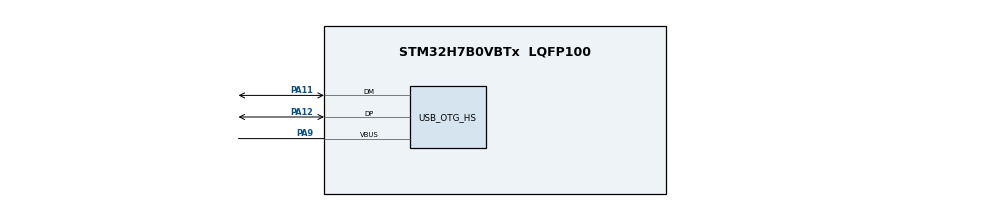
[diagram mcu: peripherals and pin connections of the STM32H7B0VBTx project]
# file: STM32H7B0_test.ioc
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Mcu.Family=STM32H7
Mcu.Name=STM32H7B0VBTx
Mcu.Package=LQFP100
NVIC.OTG_HS_IRQn=true\:0\:0\:false\:false\:true\:true\:true
NVIC.PriorityGroup=NVIC_PRIORITYGROUP_4
PA11.Mode=Device_Only_FS
PA11.Signal=USB_OTG_HS_DM
PA12.Mode=Device_Only_FS
PA12.Signal=USB_OTG_HS_DP
PA13.Mode=Serial_Wire
PA13.Signal=DEBUG_JTMS-SWDIO
PA14.Mode=Serial_Wire
PA14.Signal=DEBUG_JTCK-SWCLK
PA9.Mode=Activate_VBUS_FS
PA9.Signal=USB_OTG_HS_VBUS
ProjectManager.HeapSize=0x200
ProjectManager.StackSize=0x400
ProjectManager.TargetToolchain=STM32CubeIDE
RCC.ADCFreq_Value=129000000
RCC.APB1Freq_Value=32000000
RCC.APB2Freq_Value=32000000
RCC.APB3Freq_Value=32000000
RCC.APB4Freq_Value=32000000
RCC.CDPPRE=RCC_APB3_DIV2
RCC.CDPPRE1=RCC_APB1_DIV2
RCC.CDPPRE2=RCC_APB2_DIV2
RCC.CortexFreq_Value=64000000
RCC.DIVM1=4
RCC.DIVM3=1
RCC.DIVN1=8
RCC.DIVN3=24
RCC.DIVQ1=3
RCC.DIVQ3=8
RCC.HCLKFreq_Value=64000000
RCC.HSE_VALUE=16000000
RCC.PLL2FRACN=0
RCC.PLL3FRACN=0
RCC.PLLFRACN=0
RCC.SRDPPRE=RCC_APB4_DIV2
RCC.SYSCLKFreq_VALUE=64000000
RCC.SYSCLKSource=RCC_SYSCLKSOURCE_PLLCLK
RCC.USBCLockSelection=RCC_USBCLKSOURCE_HSI48
RCC.USBFreq_Value=48000000
USB_DEVICE.CLASS_NAME_HS=HID
USB_DEVICE.VirtualMode-HID_HS=Hid
USB_DEVICE.VirtualModeHS=Hid_HS
USB_OTG_HS.VirtualMode-Device_Only_FS=Device_Only_FS
USB_OTG_HS.dma_enable-Device_Only_FS=ENABLE
VP_USB_DEVICE_VS_USB_DEVICE_HID_HS.Mode=HID_HS
board=custom

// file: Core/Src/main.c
/* USER CODE BEGIN Header */
/**
  ******************************************************************************
  * @file           : main.c
  * @brief          : Main program body
  ******************************************************************************
  * @attention
  *
  * <h2><center>&copy; Copyright (c) 2024 STMicroelectronics.
  * All rights reserved.</center></h2>
  *
  * This software component is licensed by ST under BSD 3-Clause license,
  * the "License"; You may not use this file except in compliance with the
  * License. You may obtain a copy of the License at:
  *                        opensource.org/licenses/BSD-3-Clause
  *
  ******************************************************************************
  */
/* USER CODE END Header */
#include "main.h"
#include "usb_device.h"

/* USER CODE BEGIN PTD */
typedef struct
{
	char mouse_abs_left : 1;	//鼠标左键单击
	char mouse_abs_right : 1;	//鼠标右键单击
	char mouse_abs_wheel : 1;	//鼠标中键单击
	char reserve : 5;			//常量0
	char mouse_rel_x;			//鼠标X轴移动偏移量
	char mouse_rel_y;			//鼠标Y轴移动偏移量
	char mouse_rel_wheel;		//鼠标滚轮移动偏移�?
}	Mouse_data_t;

/* USER CODE END PTD */

/* USER CODE BEGIN PV */
extern USBD_HandleTypeDef hUsbDeviceHS;
Mouse_data_t mouse_data = {0};
int8_t xinc = 0, yinc = 0, step = 100;
uint16_t pacer = 0, cnt = 0;
const uint16_t interval_ms = 5000;
/* USER CODE END PV */

void SystemClock_Config(void);
static void MX_GPIO_Init(void);

int main(void)
{

  /* MCU Configuration--------------------------------------------------------*/

  /* Reset of all peripherals, Initializes the Flash interface and the Systick. */
  HAL_Init();

  /* Configure the system clock */
  SystemClock_Config();

  /* Initialize all configured peripherals */
  MX_GPIO_Init();
  MX_USB_DEVICE_Init();
  /* USER CODE BEGIN 2 */
  memset(&mouse_data, 0, sizeof(Mouse_data_t));
  /* USER CODE END 2 */

  /* Infinite loop */
  while (1)
  {

    /* USER CODE BEGIN 3 */
		HAL_Delay(100);
		if(pacer % (interval_ms / 100) == 0)
		{

		  switch(cnt % 4)
		  {
			  case 0: // move x
				  xinc = step;
				  yinc = 0;
				  break;
			  case 1:
				  xinc = 0;
				  yinc = step;
				  break;
			  case 2:
				  xinc = -step;
				  yinc = 0;
				  break;
			  case 3:
				  xinc = 0;
				  yinc = -step;
				  break;
		  }
		  ++cnt;
		  mouse_data.mouse_rel_x = xinc;
		  mouse_data.mouse_rel_y = yinc;
		  USBD_HID_SendReport(&hUsbDeviceHS, (uint8_t *)&mouse_data, sizeof(Mouse_data_t));
		  HAL_Delay(100);
		}
//	  HAL_IWDG_Refresh(&hiwdg); // feed the dog
	  ++pacer;
  }
  /* USER CODE END 3 */
}

void SystemClock_Config(void)
{
  RCC_OscInitTypeDef RCC_OscInitStruct = {0};
  RCC_ClkInitTypeDef RCC_ClkInitStruct = {0};

  /** Supply configuration update enable
  */
  HAL_PWREx_ConfigSupply(PWR_LDO_SUPPLY);
  /** Configure the main internal regulator output voltage
  */
  __HAL_PWR_VOLTAGESCALING_CONFIG(PWR_REGULATOR_VOLTAGE_SCALE3);

  while(!__HAL_PWR_GET_FLAG(PWR_FLAG_VOSRDY)) {}
  /** Initializes the RCC Oscillators according to the specified parameters
  * in the RCC_OscInitTypeDef structure.
  */
  RCC_OscInitStruct.OscillatorType = RCC_OSCILLATORTYPE_HSI48|RCC_OSCILLATORTYPE_HSI;
  RCC_OscInitStruct.HSIState = RCC_HSI_DIV1;
  RCC_OscInitStruct.HSICalibrationValue = RCC_HSICALIBRATION_DEFAULT;
  RCC_OscInitStruct.HSI48State = RCC_HSI48_ON;
  RCC_OscInitStruct.PLL.PLLState = RCC_PLL_ON;
  RCC_OscInitStruct.PLL.PLLSource = RCC_PLLSOURCE_HSI;
  RCC_OscInitStruct.PLL.PLLM = 4;
  RCC_OscInitStruct.PLL.PLLN = 8;
  RCC_OscInitStruct.PLL.PLLP = 2;
  RCC_OscInitStruct.PLL.PLLQ = 3;
  RCC_OscInitStruct.PLL.PLLR = 2;
  RCC_OscInitStruct.PLL.PLLRGE = RCC_PLL1VCIRANGE_3;
  RCC_OscInitStruct.PLL.PLLVCOSEL = RCC_PLL1VCOWIDE;
  RCC_OscInitStruct.PLL.PLLFRACN = 0;
  if (HAL_RCC_OscConfig(&RCC_OscInitStruct) != HAL_OK)
  {
    Error_Handler();
  }
  /** Initializes the CPU, AHB and APB buses clocks
  */
  RCC_ClkInitStruct.ClockType = RCC_CLOCKTYPE_HCLK|RCC_CLOCKTYPE_SYSCLK
                              |RCC_CLOCKTYPE_PCLK1|RCC_CLOCKTYPE_PCLK2
                              |RCC_CLOCKTYPE_D3PCLK1|RCC_CLOCKTYPE_D1PCLK1;
  RCC_ClkInitStruct.SYSCLKSource = RCC_SYSCLKSOURCE_PLLCLK;
  RCC_ClkInitStruct.SYSCLKDivider = RCC_SYSCLK_DIV1;
  RCC_ClkInitStruct.AHBCLKDivider = RCC_HCLK_DIV1;
  RCC_ClkInitStruct.APB3CLKDivider = RCC_APB3_DIV2;
  RCC_ClkInitStruct.APB1CLKDivider = RCC_APB1_DIV2;
  RCC_ClkInitStruct.APB2CLKDivider = RCC_APB2_DIV2;
  RCC_ClkInitStruct.APB4CLKDivider = RCC_APB4_DIV2;

  if (HAL_RCC_ClockConfig(&RCC_ClkInitStruct, FLASH_LATENCY_2) != HAL_OK)
  {
    Error_Handler();
  }
}

static void MX_GPIO_Init(void)
{

  /* GPIO Ports Clock Enable */
  __HAL_RCC_GPIOA_CLK_ENABLE();

}

void Error_Handler(void)
{
  __disable_irq();
  while (1)
  {
  }
}

/************************ (C) COPYRIGHT STMicroelectronics *****END OF FILE****/
